# PIC32MX274F256D register map
Registers are 32-bit, access not given, reset 0x0 unless marked. A register's access mark holds for its fields unless they carry their own. Offsets are from the block's base; lines under a group give offsets from that group; [hi:lo] are bit positions; {n}, {i} and the like mark numbered series; 'fields as' and 'values as' point back to an identical list; <NAME> marks a mode.

## Memory map
0xBF800000 DSCTRL — DSCTRL peripheral
0xBF800200 RTCC — RTCC peripheral
0xBF800600 TMR1 — TMR1 peripheral
0xBF800800 TMR2 — TMR2 peripheral
0xBF800A00 TMR3 — TMR3 peripheral
0xBF800C00 TMR4 — TMR4 peripheral
0xBF800E00 TMR5 — TMR5 peripheral
0xBF802000 ICAP1 — ICAP1 peripheral
0xBF802200 ICAP2 — ICAP2 peripheral
0xBF802400 ICAP3 — ICAP3 peripheral
0xBF802600 ICAP4 — ICAP4 peripheral
0xBF802800 ICAP5 — ICAP5 peripheral
0xBF803000 OCMP1 — OCMP1 peripheral
0xBF803200 OCMP2 — OCMP2 peripheral
0xBF803400 OCMP3 — OCMP3 peripheral
0xBF803600 OCMP4 — OCMP4 peripheral
0xBF803800 OCMP5 — OCMP5 peripheral
0xBF805000 I2C1 — I2C1 peripheral
0xBF805100 I2C2 — I2C2 peripheral
0xBF805800 SPI1 — SPI1 peripheral
0xBF805A00 SPI2 — SPI2 peripheral
0xBF806000 UART1 — UART1 peripheral
0xBF806200 UART2 — UART2 peripheral
0xBF807000 PMP — PMP peripheral
0xBF809000 ADC10 — ADC10 peripheral
0xBF809800 CVR — CVR peripheral
0xBF80A000 CMP1 — CMP1 peripheral
0xBF80A010 CMP2 — CMP2 peripheral
0xBF80A020 CMP3 — CMP3 peripheral
0xBF80A060 CMP — CMP peripheral
0xBF80A200 CTMU — CTMU peripheral
0xBF80F000 CRU — CRU peripheral
0xBF80F200 CFG — CFG peripheral
0xBF80F400 NVM — NVM peripheral
0xBF80F600 WDT — WDT peripheral
0xBF80FA04 PPS — PPS peripheral
0xBF80FC00 HLVD — HLVD peripheral
0xBF881000 INT — INT peripheral
0xBF882000 BMX — BMX peripheral
0xBF883000 DMAC — DMAC peripheral
0xBF883060 DMAC0 — DMAC0 peripheral
0xBF883120 DMAC1 — DMAC1 peripheral
0xBF8831E0 DMAC2 — DMAC2 peripheral
0xBF8832A0 DMAC3 — DMAC3 peripheral
0xBF884000 PCACHE — PCACHE peripheral
0xBF885040 USB — USB peripheral
0xBF886000 PORTA — PORTA peripheral
0xBF886100 PORTB — PORTB peripheral
0xBF886200 PORTC — PORTC peripheral

## Interrupts
0 CORE_TIMER (INT)
1 CORE_SOFTWARE_0 (INT)
2 CORE_SOFTWARE_1 (INT)
3 EXTERNAL_0 (INT)
4 TIMER_1 (INT)
5 INPUT_CAPTURE_1 (INT)
6 OUTPUT_COMPARE_1 (INT)
7 EXTERNAL_1 (INT)
8 TIMER_2 (INT)
9 INPUT_CAPTURE_2 (INT)
10 OUTPUT_COMPARE_2 (INT)
11 EXTERNAL_2 (INT)
12 TIMER_3 (INT)
13 INPUT_CAPTURE_3 (INT)
14 OUTPUT_COMPARE_3 (INT)
15 EXTERNAL_3 (INT)
16 TIMER_4 (INT)
17 INPUT_CAPTURE_4 (INT)
18 OUTPUT_COMPARE_4 (INT)
19 EXTERNAL_4 (INT)
20 TIMER_5 (INT)
21 INPUT_CAPTURE_5 (INT)
22 OUTPUT_COMPARE_5 (INT)
23 ADC (INT)
24 FAIL_SAFE_MONITOR (INT)
25 RTCC (INT)
26 FCE (INT)
27 COMPARATOR_1 (INT)
28 COMPARATOR_2 (INT)
29 COMPARATOR_3 (INT)
30 USB_1 (INT)
31 SPI_1 (INT)
32 UART_1 (INT)
33 I2C_1 (INT)
34 CHANGE_NOTICE (INT)
35 PMP (INT)
36 SPI_2 (INT)
37 UART_2 (INT)
38 I2C_2 (INT)
39 CTMU (INT)
40 DMA_0 (INT)
41 DMA_1 (INT)
42 DMA_2 (INT)
43 DMA_3 (INT)

## DSCTRL — DSCTRL peripheral
Base 0xBF800000
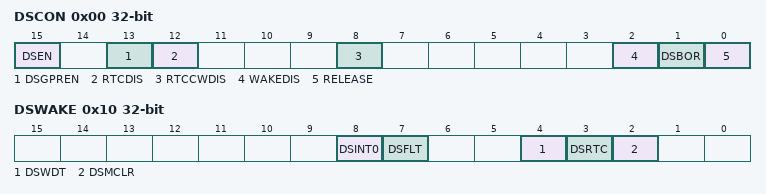
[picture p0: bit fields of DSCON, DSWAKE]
0x00 DSCON
  [15] DSEN, [13] DSGPREN, [12] RTCDIS, [8] RTCCWDIS, [2] WAKEDIS, [1] DSBOR, [0] RELEASE
0x10 DSWAKE
  [8] DSINT0, [7] DSFLT, [4] DSWDT, [3] DSRTC, [2] DSMCLR
0x20 DSGPR0
  [31:0] DSGPR
{0x3C+4i} DSGPR{i} (i=1..32)
  [31:0] DSGPR

## RTCC — RTCC peripheral
Base 0xBF800200
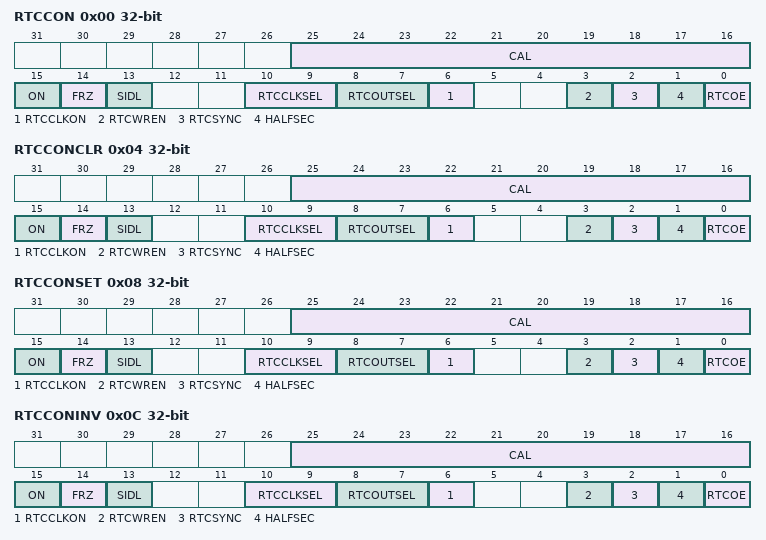
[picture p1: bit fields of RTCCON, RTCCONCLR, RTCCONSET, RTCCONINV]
0x00 RTCCON
  [25:16] CAL, [15] ON, [14] FRZ, [13] SIDL, [10:9] RTCCLKSEL, [8:7] RTCOUTSEL, [6] RTCCLKON, [3] RTCWREN, [2] RTCSYNC, [1] HALFSEC, [0] RTCOE
0x04 RTCCONCLR
  fields as RTCCON
0x08 RTCCONSET
  fields as RTCCON
0x0C RTCCONINV
  fields as RTCCON
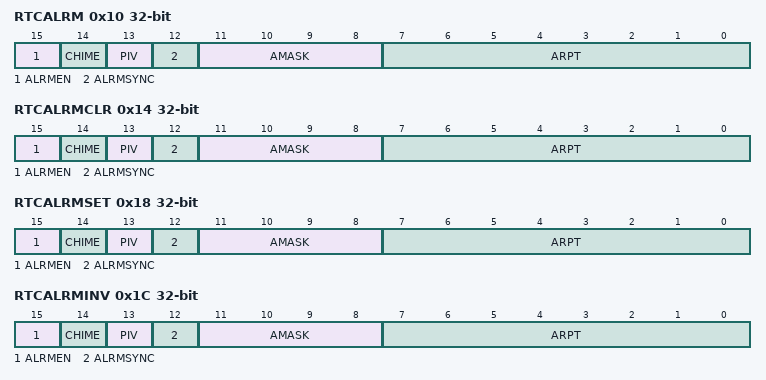
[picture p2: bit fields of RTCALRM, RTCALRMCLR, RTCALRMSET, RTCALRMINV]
0x10 RTCALRM
  [15] ALRMEN, [14] CHIME, [13] PIV, [12] ALRMSYNC, [11:8] AMASK, [7:0] ARPT
0x14 RTCALRMCLR
  fields as RTCALRM
0x18 RTCALRMSET
  fields as RTCALRM
0x1C RTCALRMINV
  fields as RTCALRM
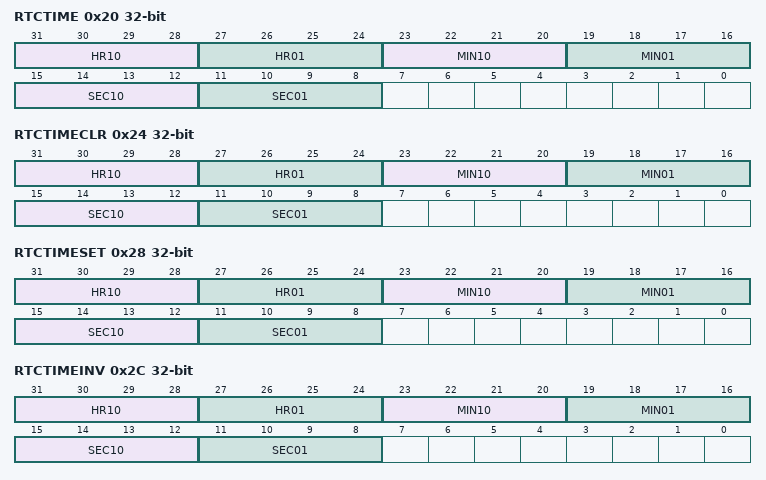
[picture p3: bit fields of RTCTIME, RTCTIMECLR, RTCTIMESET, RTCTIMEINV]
0x20 RTCTIME
  [31:28] HR10, [27:24] HR01, [23:20] MIN10, [19:16] MIN01, [15:12] SEC10, [11:8] SEC01
0x24 RTCTIMECLR
  fields as RTCTIME
0x28 RTCTIMESET
  fields as RTCTIME
0x2C RTCTIMEINV
  fields as RTCTIME
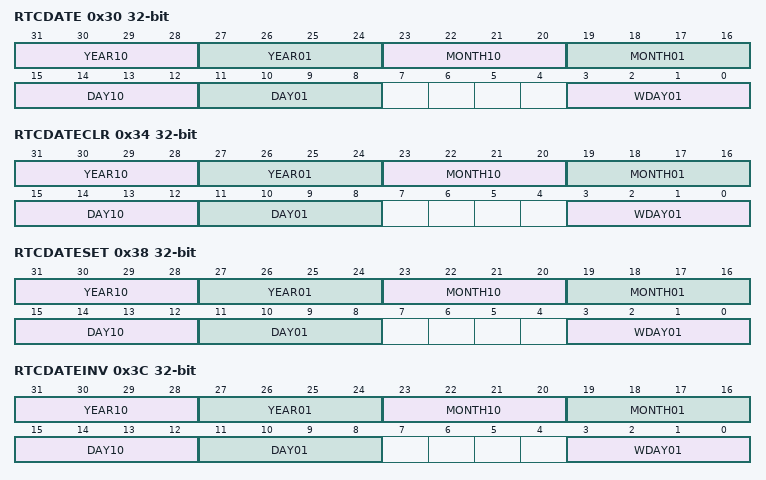
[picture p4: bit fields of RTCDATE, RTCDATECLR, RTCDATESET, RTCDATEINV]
0x30 RTCDATE
  [31:28] YEAR10, [27:24] YEAR01, [23:20] MONTH10, [19:16] MONTH01, [15:12] DAY10, [11:8] DAY01, [3:0] WDAY01
0x34 RTCDATECLR
  fields as RTCDATE
0x38 RTCDATESET
  fields as RTCDATE
0x3C RTCDATEINV
  fields as RTCDATE
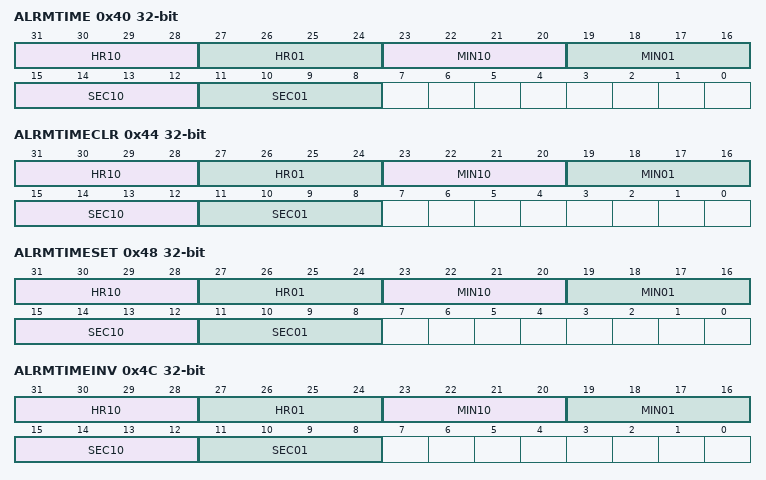
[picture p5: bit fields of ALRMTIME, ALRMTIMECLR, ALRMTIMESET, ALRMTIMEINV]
0x40 ALRMTIME
  fields as RTCTIME
0x44 ALRMTIMECLR
  fields as RTCTIME
0x48 ALRMTIMESET
  fields as RTCTIME
0x4C ALRMTIMEINV
  fields as RTCTIME
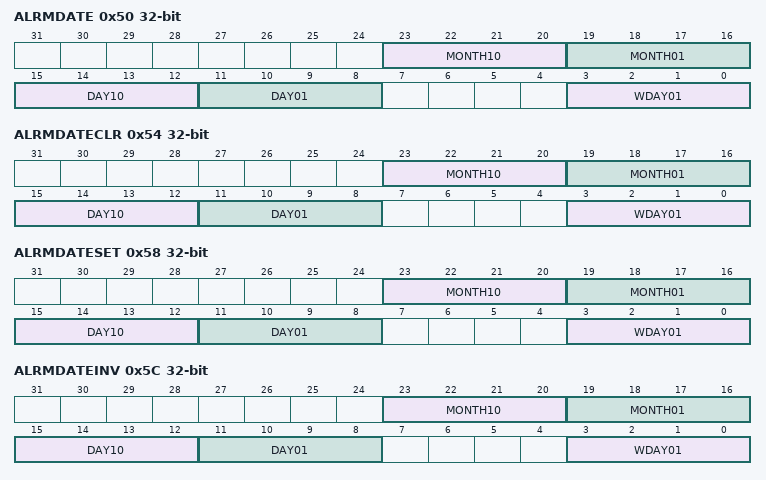
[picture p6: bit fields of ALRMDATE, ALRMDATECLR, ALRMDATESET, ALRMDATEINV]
0x50 ALRMDATE
  [23:20] MONTH10, [19:16] MONTH01, [15:12] DAY10, [11:8] DAY01, [3:0] WDAY01
0x54 ALRMDATECLR
  fields as ALRMDATE
0x58 ALRMDATESET
  fields as ALRMDATE
0x5C ALRMDATEINV
  fields as ALRMDATE
